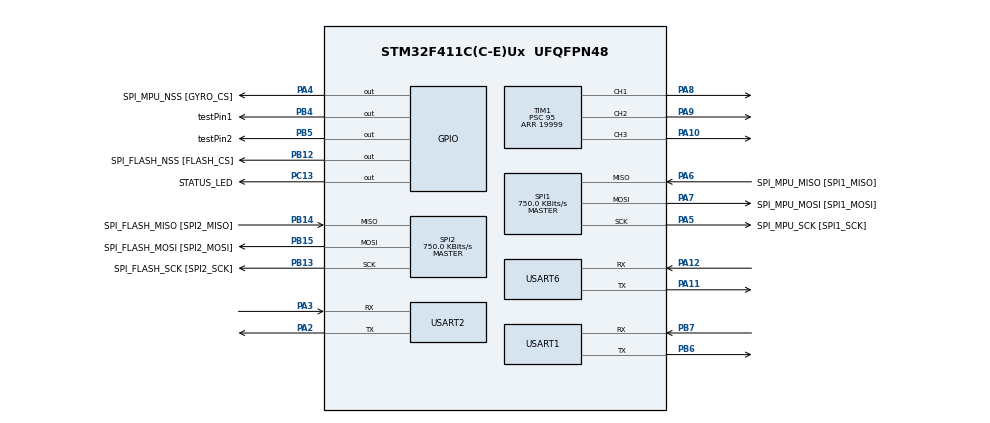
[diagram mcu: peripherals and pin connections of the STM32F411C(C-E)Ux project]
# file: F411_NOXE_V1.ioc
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Dma.Request0=USART1_RX
Dma.Request1=USART2_TX
Dma.USART1_RX.0.Direction=DMA_PERIPH_TO_MEMORY
Dma.USART1_RX.0.FIFOMode=DMA_FIFOMODE_DISABLE
Dma.USART1_RX.0.Instance=DMA2_Stream2
Dma.USART1_RX.0.MemDataAlignment=DMA_MDATAALIGN_BYTE
Dma.USART1_RX.0.MemInc=DMA_MINC_ENABLE
Dma.USART1_RX.0.Mode=DMA_NORMAL
Dma.USART1_RX.0.PeriphDataAlignment=DMA_PDATAALIGN_BYTE
Dma.USART1_RX.0.PeriphInc=DMA_PINC_DISABLE
Dma.USART1_RX.0.Priority=DMA_PRIORITY_LOW
Dma.USART2_TX.1.Direction=DMA_MEMORY_TO_PERIPH
Dma.USART2_TX.1.FIFOMode=DMA_FIFOMODE_DISABLE
Dma.USART2_TX.1.Instance=DMA1_Stream6
Dma.USART2_TX.1.MemDataAlignment=DMA_MDATAALIGN_BYTE
Dma.USART2_TX.1.MemInc=DMA_MINC_ENABLE
Dma.USART2_TX.1.Mode=DMA_NORMAL
Dma.USART2_TX.1.PeriphDataAlignment=DMA_PDATAALIGN_BYTE
Dma.USART2_TX.1.PeriphInc=DMA_PINC_DISABLE
Dma.USART2_TX.1.Priority=DMA_PRIORITY_LOW
Mcu.Family=STM32F4
Mcu.Name=STM32F411C(C-E)Ux
Mcu.Package=UFQFPN48
NVIC.DMA1_Stream6_IRQn=true\:0\:0\:false\:false\:false\:false\:true
NVIC.DMA2_Stream2_IRQn=true\:0\:0\:false\:false\:false\:true\:true
NVIC.PriorityGroup=NVIC_PRIORITYGROUP_4
NVIC.USART1_IRQn=true\:0\:0\:false\:false\:false\:true\:false
PA10.Signal=S_TIM1_CH3
PA11.Mode=Asynchronous
PA11.Signal=USART6_TX
PA12.Mode=Asynchronous
PA12.Signal=USART6_RX
PA13.Mode=Serial_Wire
PA13.Signal=SYS_JTMS-SWDIO
PA14.Mode=Serial_Wire
PA14.Signal=SYS_JTCK-SWCLK
PA2.Mode=Asynchronous
PA2.Signal=USART2_TX
PA3.Mode=Asynchronous
PA3.Signal=USART2_RX
PA4.GPIO_Label=SPI_MPU_NSS [GYRO_CS]
PA4.Signal=GPIO_Output
PA5.GPIO_Label=SPI_MPU_SCK [SPI1_SCK]
PA5.Mode=Full_Duplex_Master
PA5.Signal=SPI1_SCK
PA6.GPIO_Label=SPI_MPU_MISO [SPI1_MISO]
PA6.Mode=Full_Duplex_Master
PA6.Signal=SPI1_MISO
PA7.GPIO_Label=SPI_MPU_MOSI [SPI1_MOSI]
PA7.Mode=Full_Duplex_Master
PA7.Signal=SPI1_MOSI
PA8.Signal=S_TIM1_CH1
PA9.Signal=S_TIM1_CH2
PB12.GPIO_Label=SPI_FLASH_NSS [FLASH_CS]
PB12.Signal=GPIO_Output
PB13.GPIO_Label=SPI_FLASH_SCK [SPI2_SCK]
PB13.Mode=Full_Duplex_Master
PB13.Signal=SPI2_SCK
PB14.GPIO_Label=SPI_FLASH_MISO [SPI2_MISO]
PB14.Mode=Full_Duplex_Master
PB14.Signal=SPI2_MISO
PB15.GPIO_Label=SPI_FLASH_MOSI [SPI2_MOSI]
PB15.Mode=Full_Duplex_Master
PB15.Signal=SPI2_MOSI
PB4.GPIO_Label=testPin1
PB4.Signal=GPIO_Output
PB5.GPIO_Label=testPin2
PB5.Signal=GPIO_Output
PB6.Mode=Asynchronous
PB6.Signal=USART1_TX
PB7.Mode=Asynchronous
PB7.Signal=USART1_RX
PC13-ANTI_TAMP.GPIO_Label=STATUS_LED
PC13-ANTI_TAMP.Signal=GPIO_Output
PH0\ -\ OSC_IN.Mode=HSE-External-Clock-Source
PH0\ -\ OSC_IN.Signal=RCC_OSC_IN
PH1\ -\ OSC_OUT.Mode=HSE-External-Clock-Source
PH1\ -\ OSC_OUT.Signal=RCC_OSC_OUT
ProjectManager.HeapSize=0x200
ProjectManager.StackSize=0x400
ProjectManager.TargetToolchain=Makefile
RCC.48MHZClocksFreq_Value=48000000
RCC.AHBFreq_Value=96000000
RCC.APB1CLKDivider=RCC_HCLK_DIV2
RCC.APB1Freq_Value=48000000
RCC.APB1TimFreq_Value=96000000
RCC.APB2Freq_Value=96000000
RCC.APB2TimFreq_Value=96000000
RCC.CortexFreq_Value=96000000
RCC.HCLKFreq_Value=96000000
RCC.HSE_VALUE=8000000
RCC.HSI_VALUE=16000000
RCC.LSE_VALUE=32768
RCC.PLLM=4
RCC.PLLN=96
RCC.PLLSourceVirtual=RCC_PLLSOURCE_HSE
RCC.SYSCLKFreq_VALUE=96000000
RCC.SYSCLKSource=RCC_SYSCLKSOURCE_PLLCLK
RCC.VCOOutputFreq_Value=192000000
SH.S_TIM1_CH1.0=TIM1_CH1,Output Compare1 CH1
SH.S_TIM1_CH2.0=TIM1_CH2,Output Compare2 CH2
SH.S_TIM1_CH3.0=TIM1_CH3,Output Compare3 CH3
SPI1.BaudRatePrescaler=SPI_BAUDRATEPRESCALER_128
SPI1.CalculateBaudRate=750.0 KBits/s
SPI1.Direction=SPI_DIRECTION_2LINES
SPI1.Mode=SPI_MODE_MASTER
SPI1.VirtualType=VM_MASTER
SPI2.BaudRatePrescaler=SPI_BAUDRATEPRESCALER_64
SPI2.CalculateBaudRate=750.0 KBits/s
SPI2.Direction=SPI_DIRECTION_2LINES
SPI2.Mode=SPI_MODE_MASTER
SPI2.VirtualType=VM_MASTER
TIM1.AutoReloadPreload=TIM_AUTORELOAD_PRELOAD_ENABLE
TIM1.BreakPolarity=TIM_BREAKPOLARITY_LOW
TIM1.Channel-Output\ Compare1\ CH1=TIM_CHANNEL_1
TIM1.Channel-Output\ Compare2\ CH2=TIM_CHANNEL_2
TIM1.Channel-Output\ Compare3\ CH3=TIM_CHANNEL_3
TIM1.OC1Preload=ENABLE
TIM1.OC2Preload=ENABLE
TIM1.OC3Preload=ENABLE
TIM1.OCMode_1=TIM_OCMODE_TIMING
TIM1.OCMode_2=TIM_OCMODE_TIMING
TIM1.OCMode_3=TIM_OCMODE_TIMING
TIM1.OCPolarity_2=TIM_OCPOLARITY_HIGH
TIM1.Period=19999
TIM1.Prescaler=95
TIM11.Period=11999
TIM11.Prescaler=7
TIM2.Period=0xFFFFFFFF
TIM2.Prescaler=95
USART1.VirtualMode=VM_ASYNC
USART2.VirtualMode=VM_ASYNC
USART6.VirtualMode=VM_ASYNC
VP_TIM11_VS_ClockSourceINT.Mode=Enable_Timer
VP_TIM1_VS_ClockSourceINT.Mode=Internal
VP_TIM2_VS_ClockSourceINT.Mode=Internal
board=custom

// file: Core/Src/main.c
/* USER CODE BEGIN Header */
/**
  ******************************************************************************
  * @file           : main.c
  * @brief          : Main program body
  ******************************************************************************
  * @attention
  *
  * <h2><center>&copy; Copyright (c) 2022 STMicroelectronics.
  * All rights reserved.</center></h2>
  *
  * This software component is licensed by ST under BSD 3-Clause license,
  * the "License"; You may not use this file except in compliance with the
  * License. You may obtain a copy of the License at:
  *                        opensource.org/licenses/BSD-3-Clause
  *
  ******************************************************************************
  */
/* USER CODE END Header */
#include "main.h"
#include "dma.h"
#include "spi.h"
#include "tim.h"
#include "usart.h"
#include "gpio.h"

void SystemClock_Config(void);

/* USER CODE BEGIN 0 */

#if !defined(ARDUINO)
/* USER CODE END 0 */

int main(void)
{

  /* MCU Configuration--------------------------------------------------------*/

  /* Reset of all peripherals, Initializes the Flash interface and the Systick. */

  LL_APB2_GRP1_EnableClock(LL_APB2_GRP1_PERIPH_SYSCFG);
  LL_APB1_GRP1_EnableClock(LL_APB1_GRP1_PERIPH_PWR);

  NVIC_SetPriorityGrouping(NVIC_PRIORITYGROUP_4);

  /* System interrupt init*/
  /* SysTick_IRQn interrupt configuration */
  NVIC_SetPriority(SysTick_IRQn, NVIC_EncodePriority(NVIC_GetPriorityGrouping(),15, 0));

  /* Configure the system clock */
  SystemClock_Config();

  /* USER CODE BEGIN SysInit */
  oav_main();
}

#endif // !defined(ARDUINO)

void MX_Init(void)
{
  /* USER CODE END SysInit */

  /* Initialize all configured peripherals */
  MX_GPIO_Init();
  MX_DMA_Init();
  MX_USART1_UART_Init();
  MX_USART2_UART_Init();
  MX_SPI1_Init();
  MX_SPI2_Init();
  MX_TIM2_Init();
  MX_TIM11_Init();
  MX_USART6_UART_Init();
  MX_TIM1_Init();
  /* USER CODE BEGIN 2 */

  LL_SYSTICK_EnableIT();

  /* USER CODE END 2 */

  /* Infinite loop */
  /* USER CODE BEGIN WHILE */
#if 0

  while (1)
  {
    /* USER CODE END WHILE */

    /* USER CODE BEGIN 3 */
  }
#endif

  /* USER CODE END 3 */
}

void SystemClock_Config(void)
{
  LL_FLASH_SetLatency(LL_FLASH_LATENCY_3);
  while(LL_FLASH_GetLatency()!= LL_FLASH_LATENCY_3)
  {
  }
  LL_PWR_SetRegulVoltageScaling(LL_PWR_REGU_VOLTAGE_SCALE1);
  LL_RCC_HSE_EnableBypass();
  LL_RCC_HSE_Enable();

   /* Wait till HSE is ready */
  while(LL_RCC_HSE_IsReady() != 1)
  {

  }
  LL_RCC_PLL_ConfigDomain_SYS(LL_RCC_PLLSOURCE_HSE, LL_RCC_PLLM_DIV_4, 96, LL_RCC_PLLP_DIV_2);
  LL_RCC_PLL_Enable();

   /* Wait till PLL is ready */
  while(LL_RCC_PLL_IsReady() != 1)
  {

  }
  LL_RCC_SetAHBPrescaler(LL_RCC_SYSCLK_DIV_1);
  LL_RCC_SetAPB1Prescaler(LL_RCC_APB1_DIV_2);
  LL_RCC_SetAPB2Prescaler(LL_RCC_APB2_DIV_1);
  LL_RCC_SetSysClkSource(LL_RCC_SYS_CLKSOURCE_PLL);

   /* Wait till System clock is ready */
  while(LL_RCC_GetSysClkSource() != LL_RCC_SYS_CLKSOURCE_STATUS_PLL)
  {

  }
  LL_Init1msTick(96000000);
  LL_SetSystemCoreClock(96000000);
  LL_RCC_SetTIMPrescaler(LL_RCC_TIM_PRESCALER_TWICE);
}

void Error_Handler(void)
{
  __disable_irq();
  while (1)
  {
  }
}

/************************ (C) COPYRIGHT STMicroelectronics *****END OF FILE****/
